AUTOSAR XML (schema 00044)
package /E40_Platform_System_SystemPackage/Components
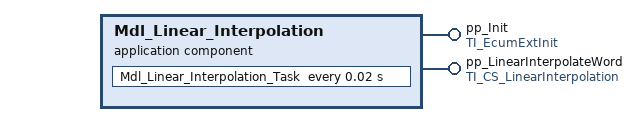
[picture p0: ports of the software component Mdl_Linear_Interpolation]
  application sw component type Mdl_Linear_Interpolation
    provide port pp_Init: server-com-spec{operation=Init, queue-length=1}, provided-interface=TI_EcumExtInit
    provide port pp_LinearInterpolateWord: provided-interface=TI_CS_LinearInterpolation
      provided-com-specs:
        operation=Get_LinearInterpolateByte, queue-length=1
        operation=Get_LinearInterpolateSByte, queue-length=1
        operation=Get_LinearInterpolateSWord, queue-length=1
        operation=Get_LinearInterpolateWord, queue-length=1
    behavior IB_Mdl_Linear_Interpolation
      5 x operation invoked event:
        OIE_pp_LinearInterpolateWord_Mdl_Linear_Interpolation_Get_LinearInterpolateByteTrigByGet_LinearInterpolateByte: start-on-event=Mdl_Linear_Interpolation_Get_LinearInterpolateByte, operation=pp_LinearInterpolateWord.Get_LinearInterpolateByte
        OIE_pp_LinearInterpolateWord_Mdl_Linear_Interpolation_Get_LinearInterpolateSByteTrigByGet_LinearInterpolateSByte: start-on-event=Mdl_Linear_Interpolation_Get_LinearInterpolateSByte, operation=pp_LinearInterpolateWord.Get_LinearInterpolateSByte
        OIE_pp_LinearInterpolateWord_Mdl_Linear_Interpolation_Get_LinearInterpolateSWordTrigByGet_LinearInterpolateSWord: start-on-event=Mdl_Linear_Interpolation_Get_LinearInterpolateSWord, operation=pp_LinearInterpolateWord.Get_LinearInterpolateSWord
        OIE_pp_LinearInterpolateWord_Mdl_Linear_Interpolation_Get_LinearInterpolateWordTrigByGet_LinearInterpolateWord: start-on-event=Mdl_Linear_Interpolation_Get_LinearInterpolateWord, operation=pp_LinearInterpolateWord.Get_LinearInterpolateWord
        OIE_pp_Init_Mdl_Linear_Interpolation_InitTrigByInit: start-on-event=Mdl_Linear_Interpolation_Init, operation=pp_Init.Init
      timing event TEMdl_Linear_Interpolation_Task: start-on-event=Mdl_Linear_Interpolation_Task, period=0.02
      port-api-options:
        enable-take-address=false, indirect-api=false, port=pp_Init
        enable-take-address=false, indirect-api=false, port=pp_LinearInterpolateWord
      6 x runnable, all with can-be-invoked-concurrently=true:
        Mdl_Linear_Interpolation_Get_LinearInterpolateByte
        Mdl_Linear_Interpolation_Get_LinearInterpolateSByte
        Mdl_Linear_Interpolation_Get_LinearInterpolateSWord
        Mdl_Linear_Interpolation_Get_LinearInterpolateWord
        Mdl_Linear_Interpolation_Init
        Mdl_Linear_Interpolation_Task
  swc implementation IMPL_Mdl_Linear_Interpolation: behavior=IB_Mdl_Linear_Interpolation
